# RZT2ME register map
Vendor: Renesas Electronics Corporation; Series: RZT; File version: 1.00.00
CPU: other r0p0, little endian, MPU, no FPU, VTOR, 4 interrupt priority bits, 624 interrupts
Registers are 32-bit, read-write, reset 0x0 unless marked. A register's access mark holds for its fields unless they carry their own. Offsets are from the block's base; [hi:lo] are bit positions; 'fields as' and 'values as' point back to an identical list.

## MTU1 — Multi-Function Timer Pulse Unit Channel 1
Base 0x90001380
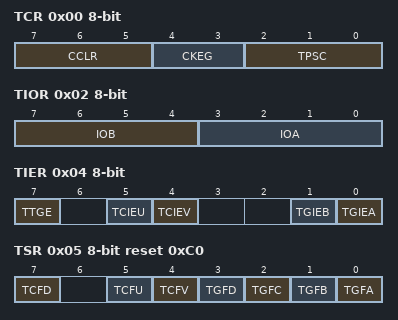
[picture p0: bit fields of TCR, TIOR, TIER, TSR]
0x00 TCR 8-bit — Timer Control Register
  [7:5] CCLR — Counter Clear Source Select
  [4:3] CKEG — Clock Edge Select
    0=Count at rising edge; 1=Count at falling edge; 0b1x=Count at both edges
  [2:0] TPSC — Time Prescaler Select
0x01 TMDR1 8-bit — Timer Mode Register 1
  [3:0] MD — Mode Select
0x02 TIOR 8-bit — Timer I/O Control Register
  [7:4] IOB — I/O Control B
  [3:0] IOA — I/O Control A
0x04 TIER 8-bit — Timer Interrupt Enable Register
  [7] TTGE — A/D Converter Start Request Enable
    0=A/D converter start request generation disabled; 1=A/D converter start request generation enabled
  [5] TCIEU — Underflow Interrupt Enable
    0=Interrupt requests (TCIU) disabled; 1=Interrupt requests (TCIU) enabled
  [4] TCIEV — Overflow Interrupt Enable
    0=Interrupt requests (TCIV) disabled; 1=Interrupt requests (TCIV) enabled
  [1] TGIEB — TGR Interrupt Enable B
    0=Interrupt requests (TGIB) disabled; 1=Interrupt requests (TGIB) enabled
  [0] TGIEA — TGR Interrupt Enable A
    0=Interrupt requests (TGIA) disabled; 1=Interrupt requests (TGIA) enabled
0x05 TSR 8-bit reset 0xC0 — Timer Status Register
  [7] TCFD ro — Count Direction Flag
    0=TCNT counts down; 1=TCNT counts up
  [5] TCFU — Underflow flag
    0=TCNT underflow has not occurred when MTU1 and MTU2 are in phase counting mode; 1=TCNT underflow has occurred when MTU1 and MTU2 are in phase counting mode
  [4] TCFV — Overflow flag
    0=TCNT overflow has not occurred; 1=TCNT overflow has occurred
  [3] TGFD — Input Capture/Output Compare Flag D
    0=TGRD input capture or compare match has not occurred; 1=TGRD input capture or compare match has occurred
  [2] TGFC — Input Capture/Output Compare Flag C
    0=TGRC input capture or compare match has not occurred; 1=TGRC input capture or compare match has occurred
  [1] TGFB — Input Capture/Output Compare Flag B
    0=TGRB input capture or compare match has not occurred; 1=TGRB input capture or compare match has occurred
  [0] TGFA — Input Capture/Output Compare Flag A
    0=TGRA input capture or compare match has not occurred; 1=TGRA input capture or compare match has occurred
0x06 TCNT 16-bit — Timer Counter
0x08 TGRA 16-bit reset 0xFFFF — Timer General Register A
0x0A TGRB 16-bit reset 0xFFFF — Timer General Register B
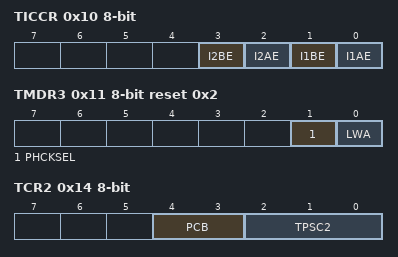
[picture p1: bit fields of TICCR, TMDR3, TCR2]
0x10 TICCR 8-bit — Timer Input Capture Control Register
  [3] I2BE — Input Capture Enable
    0=Does not include the MTIOC2B pin in the MTU1.TGRB input capture conditions; 1=Includes the MTIOC2B pin in the MTU1.TGRB input capture conditions
  [2] I2AE — Input Capture Enable
    0=Does not include the MTIOC2A pin in the MTU1.TGRA input capture conditions; 1=Includes the MTIOC2A pin in the MTU1.TGRA input capture conditions
  [1] I1BE — Input Capture Enable
    0=Does not include the MTIOC1B pin in the MTU2.TGRB input capture conditions; 1=Includes the MTIOC1B pin in the MTU2.TGRB input capture conditions
  [0] I1AE — Input Capture Enable
    0=Does not include the MTIOC1A pin in the MTU2.TGRA input capture conditions; 1=Includes the MTIOC1A pin in the MTU2.TGRA input capture conditions
0x11 TMDR3 8-bit reset 0x2 — Timer Mode Register 3
  [1] PHCKSEL — External Input Phase Clock Select
    0=MTCLKA and MTCLKB are selected for the external phase clock; 1=MTCLKC and MTCLKD are selected for the external phase clock
  [0] LWA — MTU1/MTU2 Combination Longword Access Control
    0=16-bit access is enabled; 1=32-bit access is enabled
0x14 TCR2 8-bit — Timer Control Register 2
  [4:3] PCB — Functional Expansion Control for Phase Counting Modes 2, 3, and 5
  [2:0] TPSC2 — Time Prescaler Select
0x20 TCNTLW — Timer Longword Counter
0x24 TGRALW reset 0xFFFFFFFF — Timer Longword General Register A
0x28 TGRBLW reset 0xFFFFFFFF — Timer Longword General Register B

## MTU2 — Multi-Function Timer Pulse Unit Channel 2
Base 0x90001400
Registers as MTU1, without TICCR, TMDR3, TCR2, TCNTLW, TGRALW, TGRBLW; these are added or differ:
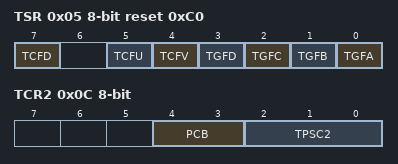
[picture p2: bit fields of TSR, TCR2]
0x05 TSR 8-bit reset 0xC0 — Timer Status Register
  fields as MTU1.TSR
0x0C TCR2 8-bit — Timer Control Register 2
  [4:3] PCB — Functional Expansion Control for Phase Counting Modes 2, 3, and 5
  [2:0] TPSC2 — Time Prescaler Select
